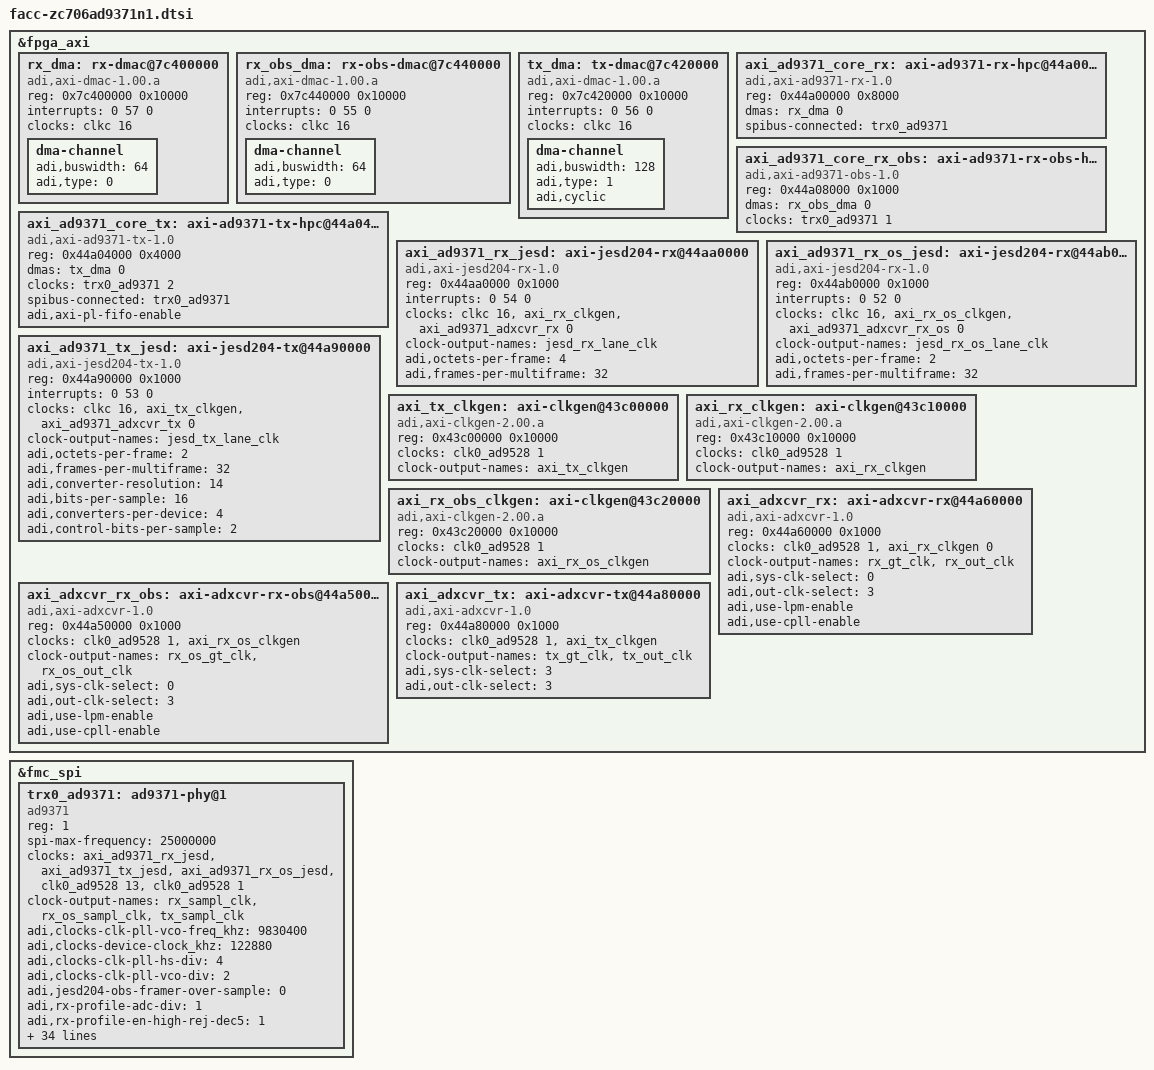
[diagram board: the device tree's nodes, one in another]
&fpga_axi {

	rx_dma: rx-dmac@7c400000 {
		compatible = "adi,axi-dmac-1.00.a";
		reg = <0x7c400000 0x10000>;
		#dma-cells = <1>;
		interrupts = <0 57 0>;
		clocks = <&clkc 16>;

		dma-channel {
			adi,buswidth = <64>;
			adi,type = <0>;
		};
	};

	rx_obs_dma: rx-obs-dmac@7c440000  {
		compatible = "adi,axi-dmac-1.00.a";
		reg = <0x7c440000  0x10000>;
		#dma-cells = <1>;
		interrupts = <0 55 0>;
		clocks = <&clkc 16>;

		dma-channel {
			adi,buswidth = <64>;
			adi,type = <0>;
		};
	};

	tx_dma: tx-dmac@7c420000 {
		compatible = "adi,axi-dmac-1.00.a";
		reg = <0x7c420000 0x10000>;
		#dma-cells = <1>;
		interrupts = <0 56 0>;
		clocks = <&clkc 16>;

		dma-channel {
			adi,buswidth = <128>;
			adi,type = <1>;
			adi,cyclic;
		};
	};

	axi_ad9371_core_rx: axi-ad9371-rx-hpc@44a00000 {
		compatible = "adi,axi-ad9371-rx-1.0";
		reg = <0x44a00000 0x8000>;
		dmas = <&rx_dma 0>;
		dma-names = "rx";
		spibus-connected = <&trx0_ad9371>;
	};

	axi_ad9371_core_rx_obs: axi-ad9371-rx-obs-hpc@44a08000 {
		compatible = "adi,axi-ad9371-obs-1.0";
		reg = <0x44a08000 0x1000>;
		dmas = <&rx_obs_dma 0>;
		dma-names = "rx";
		clocks = <&trx0_ad9371 1>;
		clock-names = "sampl_clk";
	};

	axi_ad9371_core_tx: axi-ad9371-tx-hpc@44a04000 {
		compatible = "adi,axi-ad9371-tx-1.0";
		reg = <0x44a04000 0x4000>;
		dmas = <&tx_dma 0>;
		dma-names = "tx";
		clocks = <&trx0_ad9371 2>;
		clock-names = "sampl_clk";
		spibus-connected = <&trx0_ad9371>;
		adi,axi-pl-fifo-enable;
	};

	axi_ad9371_rx_jesd: axi-jesd204-rx@44aa0000 {
		compatible = "adi,axi-jesd204-rx-1.0";
		reg = <0x44aa0000 0x1000>;

		interrupts = <0 54 0>;

		clocks = <&clkc 16>, <&axi_rx_clkgen>, <&axi_ad9371_adxcvr_rx 0>;
		clock-names = "s_axi_aclk", "device_clk", "lane_clk";

		#clock-cells = <0>;
		clock-output-names = "jesd_rx_lane_clk";

		adi,octets-per-frame = <4>;
		adi,frames-per-multiframe = <32>;
	};

	axi_ad9371_rx_os_jesd: axi-jesd204-rx@44ab0000 {
		compatible = "adi,axi-jesd204-rx-1.0";
		reg = <0x44ab0000 0x1000>;

		interrupts = <0 52 0>;

		clocks = <&clkc 16>, <&axi_rx_os_clkgen>, <&axi_ad9371_adxcvr_rx_os 0>;
		clock-names = "s_axi_aclk", "device_clk", "lane_clk";

		#clock-cells = <0>;
		clock-output-names = "jesd_rx_os_lane_clk";

		adi,octets-per-frame = <2>;
		adi,frames-per-multiframe = <32>;
	};

	axi_ad9371_tx_jesd: axi-jesd204-tx@44a90000 {
		compatible = "adi,axi-jesd204-tx-1.0";
		reg = <0x44a90000 0x1000>;

		interrupts = <0 53 0>;

		clocks = <&clkc 16>, <&axi_tx_clkgen>, <&axi_ad9371_adxcvr_tx 0>;
		clock-names = "s_axi_aclk", "device_clk", "lane_clk";

		#clock-cells = <0>;
		clock-output-names = "jesd_tx_lane_clk";

		adi,octets-per-frame = <2>;
		adi,frames-per-multiframe = <32>;
		adi,converter-resolution = <14>;
		adi,bits-per-sample = <16>;
		adi,converters-per-device = <4>;
		adi,control-bits-per-sample = <2>;
	};


	axi_tx_clkgen: axi-clkgen@43c00000  {
		compatible = "adi,axi-clkgen-2.00.a";
		reg = <0x43c00000 0x10000>;
		#clock-cells = <0>;
		clocks = <&clk0_ad9528 1>;
		clock-output-names = "axi_tx_clkgen";
	};

	axi_rx_clkgen: axi-clkgen@43c10000  {
		compatible = "adi,axi-clkgen-2.00.a";
		reg = <0x43c10000 0x10000>;
		#clock-cells = <0>;
		clocks = <&clk0_ad9528 1>;
		clock-output-names = "axi_rx_clkgen";
	};

	axi_rx_obs_clkgen: axi-clkgen@43c20000  {
		compatible = "adi,axi-clkgen-2.00.a";
		reg = <0x43c20000 0x10000>;
		#clock-cells = <0>;
		clocks = <&clk0_ad9528 1>;
		clock-output-names = "axi_rx_os_clkgen";
	};

	axi_adxcvr_rx: axi-adxcvr-rx@44a60000 {
		#address-cells = <1>;
		#size-cells = <0>;
		compatible = "adi,axi-adxcvr-1.0";
		reg = <0x44a60000 0x1000>;

		clocks = <&clk0_ad9528 1>, <&axi_rx_clkgen 0>;
		clock-names = "conv", "div40";

		#clock-cells = <1>;
		clock-output-names = "rx_gt_clk", "rx_out_clk";

		adi,sys-clk-select = <0>;
		adi,out-clk-select = <3>;
		adi,use-lpm-enable;
		adi,use-cpll-enable;
	};

	axi_adxcvr_rx_obs: axi-adxcvr-rx-obs@44a50000 {
		#address-cells = <1>;
		#size-cells = <0>;
		compatible = "adi,axi-adxcvr-1.0";
		reg = <0x44a50000 0x1000>;

		clocks = <&clk0_ad9528 1>, <&axi_rx_os_clkgen>;
		clock-names = "conv", "div40";

		#clock-cells = <1>;
		clock-output-names = "rx_os_gt_clk", "rx_os_out_clk";

		adi,sys-clk-select = <0>;
		adi,out-clk-select = <3>;
		adi,use-lpm-enable;
		adi,use-cpll-enable;
	};

	axi_adxcvr_tx: axi-adxcvr-tx@44a80000 {
		#address-cells = <1>;
		#size-cells = <0>;
		compatible = "adi,axi-adxcvr-1.0";
		reg = <0x44a80000 0x1000>;

		clocks = <&clk0_ad9528 1>, <&axi_tx_clkgen>;
		clock-names = "conv", "div40";

		#clock-cells = <1>;
		clock-output-names = "tx_gt_clk", "tx_out_clk";

		adi,sys-clk-select = <3>;
		adi,out-clk-select = <3>;
	};
};

&fmc_spi {
	trx0_ad9371: ad9371-phy@1 {
		#address-cells = <1>;
		#size-cells = <0>;
		#clock-cells = <1>;
		compatible = "ad9371";

		/* SPI Setup */
		reg = <1>;
		spi-max-frequency = <25000000>;

		/* Clocks */
		clocks = <&axi_ad9371_rx_jesd>, <&axi_ad9371_tx_jesd>, <&axi_ad9371_rx_os_jesd>, <&clk0_ad9528 13>, <&clk0_ad9528 1>;
		clock-names = "jesd_rx_clk", "jesd_tx_clk", "jesd_rx_os_clk", "dev_clk", "fmc_clk";
		clock-output-names = "rx_sampl_clk", "rx_os_sampl_clk", "tx_sampl_clk";

		adi,clocks-clk-pll-vco-freq_khz = <9830400>;
		adi,clocks-device-clock_khz = <122880>;
		adi,clocks-clk-pll-hs-div = <4>;
		adi,clocks-clk-pll-vco-div = <2>;

		adi,jesd204-obs-framer-over-sample = <0>;

		adi,rx-profile-adc-div = <1>;
		adi,rx-profile-en-high-rej-dec5 = <1>;
		adi,rx-profile-iq-rate_khz = <122880>;
		adi,rx-profile-rf-bandwidth_hz = <100000000>;
		adi,rx-profile-rhb1-decimation = <1>;
		adi,rx-profile-rx-bbf-3db-corner_khz = <100000>;
		adi,rx-profile-rx-dec5-decimation = <5>;
		adi,rx-profile-rx-fir-decimation = <2>;

		adi,obs-profile-adc-div = <1>;
		adi,obs-profile-en-high-rej-dec5 = <0>;
		adi,obs-profile-iq-rate_khz = <245760>;
		adi,obs-profile-rf-bandwidth_hz = <200000000>;
		adi,obs-profile-rhb1-decimation = <1>;
		adi,obs-profile-rx-bbf-3db-corner_khz = <100000>;
		adi,obs-profile-rx-dec5-decimation = <5>;
		adi,obs-profile-rx-fir-decimation = <1>;

		adi,tx-profile-dac-div = <1>;
		adi,tx-profile-iq-rate_khz = <245760>;
		adi,tx-profile-primary-sig-bandwidth_hz = <75000000>;
		adi,tx-profile-rf-bandwidth_hz = <200000000>;
		adi,tx-profile-thb1-interpolation = <2>;
		adi,tx-profile-thb2-interpolation = <1>;
		adi,tx-profile-tx-bbf-3db-corner_khz = <100000>;
		adi,tx-profile-tx-dac-3db-corner_khz = <189477>;
		adi,tx-profile-tx-fir-interpolation = <1>;
		adi,tx-profile-tx-input-hb-interpolation = <1>;

		adi,sniffer-profile-adc-div = <1>;
		adi,sniffer-profile-en-high-rej-dec5 = <0>;
		adi,sniffer-profile-iq-rate_khz = <30720>;
		adi,sniffer-profile-rf-bandwidth_hz = <20000000>;
		adi,sniffer-profile-rhb1-decimation = <2>;
		adi,sniffer-profile-rx-bbf-3db-corner_khz = <100000>;
		adi,sniffer-profile-rx-dec5-decimation = <5>;
		adi,sniffer-profile-rx-fir-decimation = <4>;
	};
};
